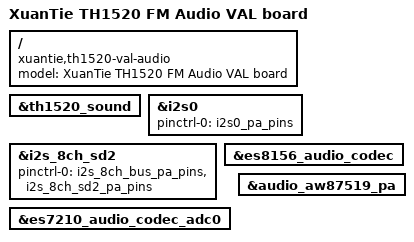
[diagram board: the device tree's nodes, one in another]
/* SPDX-License-Identifier: GPL-2.0 */
/*
 * Copyright (C) 2021 Alibaba Group Holding Limited.
 */

#include "th1520-a-val.dtsi"

/ {
	model = "XuanTie TH1520 FM Audio VAL board";
	compatible = "xuantie,th1520-val-audio", "xuantie,th1520";
};

&th1520_sound {
	status = "okay";
};

&i2s0 {
	status = "okay";
	pinctrl-names = "default";
	pinctrl-0 = <&i2s0_pa_pins>;
};

&i2s_8ch_sd2 {
	status = "okay";
	pinctrl-names = "default";
	pinctrl-0 = <&i2s_8ch_bus_pa_pins>,
				<&i2s_8ch_sd2_pa_pins>;
};

&es8156_audio_codec {
	status = "okay";
};

&es7210_audio_codec_adc0 {
	status = "okay";
};

&audio_aw87519_pa {
	status = "okay";
};
